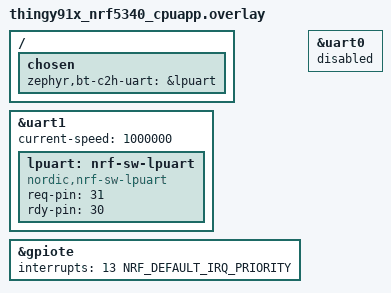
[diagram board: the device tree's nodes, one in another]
&uart1 {
	current-speed = <1000000>;
	status = "okay";

	lpuart: nrf-sw-lpuart {
		compatible = "nordic,nrf-sw-lpuart";
		status = "okay";
		req-pin = <31>;
		rdy-pin = <30>;
	};
};
&gpiote {
	interrupts = <13 NRF_DEFAULT_IRQ_PRIORITY>;
};
/ {
	chosen {
		zephyr,bt-c2h-uart=&lpuart;
	};
};
&uart0 {
	status = "disabled";
};

